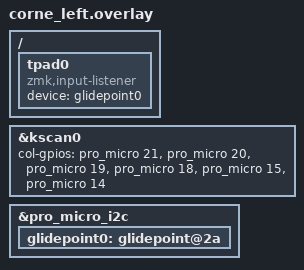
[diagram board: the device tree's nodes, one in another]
/*
 * Copyright (c) 2020 Pete Johanson
 *
 * SPDX-License-Identifier: MIT
 */

#include "corne.dtsi"

&kscan0 {
    col-gpios
        = <&pro_micro 21 GPIO_ACTIVE_HIGH>
        , <&pro_micro 20 GPIO_ACTIVE_HIGH>
        , <&pro_micro 19 GPIO_ACTIVE_HIGH>
        , <&pro_micro 18 GPIO_ACTIVE_HIGH>
        , <&pro_micro 15 GPIO_ACTIVE_HIGH>
        , <&pro_micro 14 GPIO_ACTIVE_HIGH>
        ;
};



&pro_micro_i2c {
    status = "okay";
    glidepoint0: glidepoint@2a {
        status = "okay";
    };
};


/ {
  tpad0: tpad0 {
        compatible = "zmk,input-listener";

        device = <&glidepoint0>;
        // xy-swap;
        // y-invert;
        // x-invert;
    };
};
